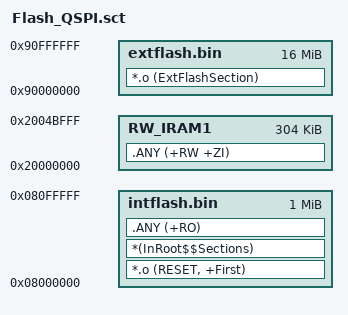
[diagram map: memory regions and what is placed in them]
LR_IROM1 0x08000000 0x00100000  {    ; load region size_region
  intflash.bin 0x08000000 0x00100000  {  ; load address = execution address
   *.o (RESET, +First)
   *(InRoot$$Sections)
   .ANY (+RO)
  }
  RW_IRAM1 0x20000000 0x0004C000  {  ; RW data
   .ANY (+RW +ZI)
  }
}

LR_EROM1 0x90000000 0x01000000  {    ; load region size_region
  extflash.bin 0x90000000 0x01000000  {  ; load address = execution address
   *.o (ExtFlashSection)
  }
}
 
